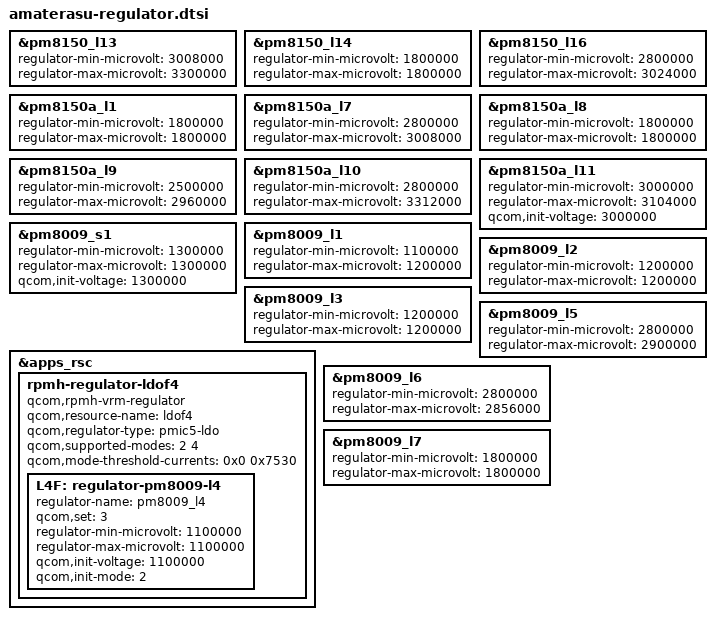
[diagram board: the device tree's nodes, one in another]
/*
 * FCNT arrows 5G (F-51A) - Regulators: board specific PM8150/PM8150A/PM8009 rails.
 *
 * Reconstructed from the FCNT stock dtbo (kona FFRD REV7 SKU3); FFRD is
 * derived from the CLO kona QRD board files.
 */

&pm8150_l13 {
	regulator-min-microvolt = <3008000>;
	regulator-max-microvolt = <3300000>;
};

&pm8150_l14 {
	regulator-min-microvolt = <1800000>;
	regulator-max-microvolt = <1800000>;
};

&pm8150_l16 {
	regulator-min-microvolt = <2800000>;
	regulator-max-microvolt = <3024000>;
};

&pm8150a_l1 {
	regulator-min-microvolt = <1800000>;
	regulator-max-microvolt = <1800000>;
};

&pm8150a_l7 {
	regulator-min-microvolt = <2800000>;
	regulator-max-microvolt = <3008000>;
};

&pm8150a_l8 {
	regulator-min-microvolt = <1800000>;
	regulator-max-microvolt = <1800000>;
};

&pm8150a_l9 {
	regulator-min-microvolt = <2500000>;
	regulator-max-microvolt = <2960000>;
};

&pm8150a_l10 {
	regulator-min-microvolt = <2800000>;
	regulator-max-microvolt = <3312000>;
};

&pm8150a_l11 {
	regulator-min-microvolt = <3000000>;
	regulator-max-microvolt = <3104000>;
	qcom,init-voltage = <3000000>;
};

&pm8009_s1 {
	regulator-min-microvolt = <1300000>;
	regulator-max-microvolt = <1300000>;
	qcom,init-voltage = <1300000>;
};

&pm8009_l1 {
	regulator-min-microvolt = <1100000>;
	regulator-max-microvolt = <1200000>;
};

&pm8009_l2 {
	regulator-min-microvolt = <1200000>;
	regulator-max-microvolt = <1200000>;
};

&pm8009_l3 {
	regulator-min-microvolt = <1200000>;
	regulator-max-microvolt = <1200000>;
};

&apps_rsc {
	rpmh-regulator-ldof4 {
		compatible = "qcom,rpmh-vrm-regulator";
		qcom,resource-name = "ldof4";
		qcom,regulator-type = "pmic5-ldo";
		qcom,supported-modes = <2 4>;
		qcom,mode-threshold-currents = <0x0 0x7530>;

		L4F: regulator-pm8009-l4 {
			regulator-name = "pm8009_l4";
			qcom,set = <3>;
			regulator-min-microvolt = <1100000>;
			regulator-max-microvolt = <1100000>;
			qcom,init-voltage = <1100000>;
			qcom,init-mode = <2>;
		};
	};
};

&pm8009_l5 {
	regulator-min-microvolt = <2800000>;
	regulator-max-microvolt = <2900000>;
};

&pm8009_l6 {
	regulator-min-microvolt = <2800000>;
	regulator-max-microvolt = <2856000>;
};

&pm8009_l7 {
	regulator-min-microvolt = <1800000>;
	regulator-max-microvolt = <1800000>;
};
